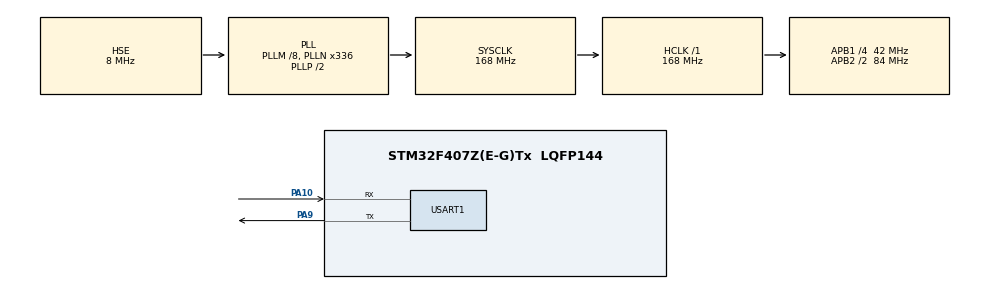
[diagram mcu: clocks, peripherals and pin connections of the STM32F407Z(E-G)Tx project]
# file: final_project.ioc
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Mcu.Family=STM32F4
Mcu.Name=STM32F407Z(E-G)Tx
Mcu.Package=LQFP144
NVIC.PriorityGroup=NVIC_PRIORITYGROUP_4
NVIC.USART1_IRQn=true\:0\:0\:false\:false\:true\:true\:true\:true
PA10.Mode=Asynchronous
PA10.Signal=USART1_RX
PA9.Mode=Asynchronous
PA9.Signal=USART1_TX
PH0-OSC_IN.Mode=HSE-External-Oscillator
PH0-OSC_IN.Signal=RCC_OSC_IN
PH1-OSC_OUT.Mode=HSE-External-Oscillator
PH1-OSC_OUT.Signal=RCC_OSC_OUT
ProjectManager.HeapSize=0x800
ProjectManager.StackSize=0x800
ProjectManager.TargetToolchain=STM32CubeIDE
RCC.48MHZClocksFreq_Value=84000000
RCC.AHBFreq_Value=168000000
RCC.APB1CLKDivider=RCC_HCLK_DIV4
RCC.APB1Freq_Value=42000000
RCC.APB1TimFreq_Value=84000000
RCC.APB2CLKDivider=RCC_HCLK_DIV2
RCC.APB2Freq_Value=84000000
RCC.APB2TimFreq_Value=168000000
RCC.CortexFreq_Value=168000000
RCC.HCLKFreq_Value=168000000
RCC.HSE_VALUE=8000000
RCC.HSI_VALUE=16000000
RCC.LSE_VALUE=32768
RCC.PLLM=8
RCC.PLLN=336
RCC.PLLSourceVirtual=RCC_PLLSOURCE_HSE
RCC.SYSCLKFreq_VALUE=168000000
RCC.SYSCLKSource=RCC_SYSCLKSOURCE_PLLCLK
RCC.VCOOutputFreq_Value=336000000
STMicroelectronics.X-CUBE-AI.8.1.0.ActivationBufferSizeList=21080
STMicroelectronics.X-CUBE-AI.8.1.0.ActivationBuffers=pool0
STMicroelectronics.X-CUBE-AI.8.1.0.ActivationNames=pool0
STMicroelectronics.X-CUBE-AI.8.1.0.ActivationSizes=AI_NETWORK_DATA_ACTIVATION_1_SIZE
STMicroelectronics.X-CUBE-AI.8.1.0.ApplicationCcDeviceJjApplication=ApplicationTemplate
STMicroelectronics.X-CUBE-AI.8.1.0.HeapSize=0x800
STMicroelectronics.X-CUBE-AI.8.1.0.InternalRamActivationBufferMaxSize=AI_NETWORK_DATA_ACTIVATIONS_SIZE
STMicroelectronics.X-CUBE-AI.8.1.0.LatestDirectoryUsed-b58da7841a62ef9f353980d400d128ae7c25407cc9f74fb228b3c24c61afa8c6=/Users/m1pro/trained_lstm
STMicroelectronics.X-CUBE-AI.8.1.0.MaximumNumberOfInputLayer=1
STMicroelectronics.X-CUBE-AI.8.1.0.MaximumNumberOfOutputLayer=1
STMicroelectronics.X-CUBE-AI.8.1.0.MaximumSizeOfInputLayer=1
STMicroelectronics.X-CUBE-AI.8.1.0.MaximumSizeOfOutputLayer=1
STMicroelectronics.X-CUBE-AI.8.1.0.ModelActualCompression-b58da7841a62ef9f353980d400d128ae7c25407cc9f74fb228b3c24c61afa8c6=0.0
STMicroelectronics.X-CUBE-AI.8.1.0.ModelCompression-b58da7841a62ef9f353980d400d128ae7c25407cc9f74fb228b3c24c61afa8c6=None
STMicroelectronics.X-CUBE-AI.8.1.0.ModelFlashOccupation-b58da7841a62ef9f353980d400d128ae7c25407cc9f74fb228b3c24c61afa8c6=131928
STMicroelectronics.X-CUBE-AI.8.1.0.ModelHashList=b58da7841a62ef9f353980d400d128ae7c25407cc9f74fb228b3c24c61afa8c6
STMicroelectronics.X-CUBE-AI.8.1.0.ModelKind-b58da7841a62ef9f353980d400d128ae7c25407cc9f74fb228b3c24c61afa8c6=ONNX
STMicroelectronics.X-CUBE-AI.8.1.0.ModelMacc-b58da7841a62ef9f353980d400d128ae7c25407cc9f74fb228b3c24c61afa8c6=7500238
STMicroelectronics.X-CUBE-AI.8.1.0.ModelName-b58da7841a62ef9f353980d400d128ae7c25407cc9f74fb228b3c24c61afa8c6=network
STMicroelectronics.X-CUBE-AI.8.1.0.ModelNameList=network
STMicroelectronics.X-CUBE-AI.8.1.0.ModelRamOccupation-b58da7841a62ef9f353980d400d128ae7c25407cc9f74fb228b3c24c61afa8c6=21080
STMicroelectronics.X-CUBE-AI.8.1.0.ModelStructureFile-b58da7841a62ef9f353980d400d128ae7c25407cc9f74fb228b3c24c61afa8c6=/Users/m1pro/trained_lstm/emnist_letters_cnn.int8.onnx
STMicroelectronics.X-CUBE-AI.8.1.0.ModelType-b58da7841a62ef9f353980d400d128ae7c25407cc9f74fb228b3c24c61afa8c6=Saved model
STMicroelectronics.X-CUBE-AI.8.1.0.ReadyForCodeGeneration=true
STMicroelectronics.X-CUBE-AI.8.1.0.StackSize=0x800
STMicroelectronics.X-CUBE-AI.8.1.0.WorkingBufferStartAddrList=0xFFFFFFFF
STMicroelectronics.X-CUBE-AI.8.1.0.XAaCUBEAaAICcArtificialOoIntelligenceJjCore=true
STMicroelectronics.X-CUBE-AI.8.1.0.copyWeightToRam=false
STMicroelectronics.X-CUBE-AI.8.1.0.copyWeightToRam-b58da7841a62ef9f353980d400d128ae7c25407cc9f74fb228b3c24c61afa8c6=false
STMicroelectronics.X-CUBE-AI.8.1.0.customLayerConfigEnabled=false
STMicroelectronics.X-CUBE-AI.8.1.0.customLayerConfigEnabled-b58da7841a62ef9f353980d400d128ae7c25407cc9f74fb228b3c24c61afa8c6=false
STMicroelectronics.X-CUBE-AI.8.1.0.noOnnxIoTranspose=false
STMicroelectronics.X-CUBE-AI.8.1.0.noOnnxIoTranspose-b58da7841a62ef9f353980d400d128ae7c25407cc9f74fb228b3c24c61afa8c6=false
STMicroelectronics.X-CUBE-AI.8.1.0.useInputAllocation=true
STMicroelectronics.X-CUBE-AI.8.1.0.useInputAllocation-b58da7841a62ef9f353980d400d128ae7c25407cc9f74fb228b3c24c61afa8c6=true
STMicroelectronics.X-CUBE-AI.8.1.0.useOutputAllocation=true
STMicroelectronics.X-CUBE-AI.8.1.0.useOutputAllocation-b58da7841a62ef9f353980d400d128ae7c25407cc9f74fb228b3c24c61afa8c6=true
USART1.VirtualMode=VM_ASYNC
VP_CRC_VS_CRC.Mode=CRC_Activate
VP_STMicroelectronics.X-CUBE-AI_VS_ArtificialOoIntelligenceJjXAaCUBEAaAI_8.1.0.Mode=ArtificialOoIntelligenceJjXAaCUBEAaAI
VP_STMicroelectronics.X-CUBE-AI_VS_DeviceJjApplication_8.1.0.Mode=DeviceJjApplication
board=custom

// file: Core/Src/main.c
/* USER CODE BEGIN Header */
/**
  ******************************************************************************
  * @file           : main.c
  * @brief          : Main program body
  ******************************************************************************
  * @attention
  *
  * Copyright (c) 2025 STMicroelectronics.
  * All rights reserved.
  *
  * This software is licensed under terms that can be found in the LICENSE file
  * in the root directory of this software component.
  * If no LICENSE file comes with this software, it is provided AS-IS.
  *
  ******************************************************************************
  */
/* USER CODE END Header */
#include "main.h"
#include "app_x-cube-ai.h"

/* USER CODE BEGIN Includes */
#include "stdio.h"
#include "string.h"
#include "app_x-cube-ai.h"

/* Keep compatibility: expose data_ins/data_outs symbols */
#include "ai_datatypes_defines.h"
extern ai_i8* data_ins[];
extern ai_i8* data_outs[];

/* Provide image feeding API from app_x-cube-ai.c */
void AI_SetBinaryImage(const uint8_t* src, uint32_t len);
/* USER CODE END Includes */

/* USER CODE BEGIN PD */
#define UART_BUFF_LEN 1024
#define ONE_FRAME_LEN 1+784+2
/* USER CODE END PD */

CRC_HandleTypeDef hcrc;

UART_HandleTypeDef huart1;

/* USER CODE BEGIN PV */
uint16_t uart_rx_length = 0;
uint8_t uart_rx_byte = 0;
uint8_t uart_rx_buffer[UART_BUFF_LEN];
volatile uint8_t goRunning = 0;
/* USER CODE END PV */

void SystemClock_Config(void);
static void MX_GPIO_Init(void);
static void MX_CRC_Init(void);
static void MX_USART1_UART_Init(void);
/* USER CODE BEGIN PFP */
void Uart_send(char * str);
/* USER CODE END PFP */

int main(void)
{

  /* MCU Configuration--------------------------------------------------------*/

  /* Reset of all peripherals, Initializes the Flash interface and the Systick. */
  HAL_Init();

  /* Configure the system clock */
  SystemClock_Config();

  /* Initialize all configured peripherals */
  MX_GPIO_Init();
  MX_CRC_Init();
  MX_USART1_UART_Init();
  MX_X_CUBE_AI_Init();
  /* USER CODE BEGIN 2 */
  memset(uart_rx_buffer,0,784);
  HAL_UART_Receive_IT(&huart1, (uint8_t *)&uart_rx_byte, 1);
  /* USER CODE END 2 */

  /* Infinite loop */
  while (1)
  {

    /* USER CODE BEGIN 3 */
  if(goRunning>0)
      {
          if(uart_rx_length == ONE_FRAME_LEN)
          {
              /* Feed 28x28 binary image (0/1) to AI input path; layout handled inside */
              AI_SetBinaryImage(uart_rx_buffer+1, 28*28);

              MX_X_CUBE_AI_Process();
          }
          memset(uart_rx_buffer,0,784);
          goRunning = 0;
          uart_rx_length = 0;
      }
  }
  /* USER CODE END 3 */
}

void SystemClock_Config(void)
{
  RCC_OscInitTypeDef RCC_OscInitStruct = {0};
  RCC_ClkInitTypeDef RCC_ClkInitStruct = {0};

  /** Configure the main internal regulator output voltage
  */
  __HAL_RCC_PWR_CLK_ENABLE();
  __HAL_PWR_VOLTAGESCALING_CONFIG(PWR_REGULATOR_VOLTAGE_SCALE1);

  /** Initializes the RCC Oscillators according to the specified parameters
  * in the RCC_OscInitTypeDef structure.
  */
  RCC_OscInitStruct.OscillatorType = RCC_OSCILLATORTYPE_HSE;
  RCC_OscInitStruct.HSEState = RCC_HSE_ON;
  RCC_OscInitStruct.PLL.PLLState = RCC_PLL_ON;
  RCC_OscInitStruct.PLL.PLLSource = RCC_PLLSOURCE_HSE;
  RCC_OscInitStruct.PLL.PLLM = 8;
  RCC_OscInitStruct.PLL.PLLN = 336;
  RCC_OscInitStruct.PLL.PLLP = RCC_PLLP_DIV2;
  RCC_OscInitStruct.PLL.PLLQ = 4;
  if (HAL_RCC_OscConfig(&RCC_OscInitStruct) != HAL_OK)
  {
    Error_Handler();
  }

  /** Initializes the CPU, AHB and APB buses clocks
  */
  RCC_ClkInitStruct.ClockType = RCC_CLOCKTYPE_HCLK|RCC_CLOCKTYPE_SYSCLK
                              |RCC_CLOCKTYPE_PCLK1|RCC_CLOCKTYPE_PCLK2;
  RCC_ClkInitStruct.SYSCLKSource = RCC_SYSCLKSOURCE_PLLCLK;
  RCC_ClkInitStruct.AHBCLKDivider = RCC_SYSCLK_DIV1;
  RCC_ClkInitStruct.APB1CLKDivider = RCC_HCLK_DIV4;
  RCC_ClkInitStruct.APB2CLKDivider = RCC_HCLK_DIV2;

  if (HAL_RCC_ClockConfig(&RCC_ClkInitStruct, FLASH_LATENCY_5) != HAL_OK)
  {
    Error_Handler();
  }
}

static void MX_CRC_Init(void)
{

  hcrc.Instance = CRC;
  if (HAL_CRC_Init(&hcrc) != HAL_OK)
  {
    Error_Handler();
  }

}

static void MX_USART1_UART_Init(void)
{

  huart1.Instance = USART1;
  huart1.Init.BaudRate = 115200;
  huart1.Init.WordLength = UART_WORDLENGTH_8B;
  huart1.Init.StopBits = UART_STOPBITS_1;
  huart1.Init.Parity = UART_PARITY_NONE;
  huart1.Init.Mode = UART_MODE_TX_RX;
  huart1.Init.HwFlowCtl = UART_HWCONTROL_NONE;
  huart1.Init.OverSampling = UART_OVERSAMPLING_16;
  if (HAL_UART_Init(&huart1) != HAL_OK)
  {
    Error_Handler();
  }

}

static void MX_GPIO_Init(void)
{

  /* GPIO Ports Clock Enable */
  __HAL_RCC_GPIOH_CLK_ENABLE();
  __HAL_RCC_GPIOA_CLK_ENABLE();

}

/* USER CODE BEGIN 4 */
void HAL_UART_RxCpltCallback(UART_HandleTypeDef *UartHandle)
{
    if(goRunning ==0)
    {
        if (uart_rx_length < UART_BUFF_LEN)
        {
            uart_rx_buffer[uart_rx_length] = uart_rx_byte;
            uart_rx_length++;

            if (uart_rx_byte == '\n')
            {
                goRunning = 1;
            }
        }
        else
        {
            uart_rx_length = 0;
        }
    }
    HAL_UART_Receive_IT(&huart1, (uint8_t *)&uart_rx_byte, 1);
}

void Uart_send(char * str)
{
    HAL_UART_Transmit(&huart1, (uint8_t *)str, strlen(str),0xffff);
}

/* No direct buffer write here; input preparation is done in app_x-cube-ai.c */
/* USER CODE END 4 */

void Error_Handler(void)
{
  __disable_irq();
  while (1)
  {
  }
}
